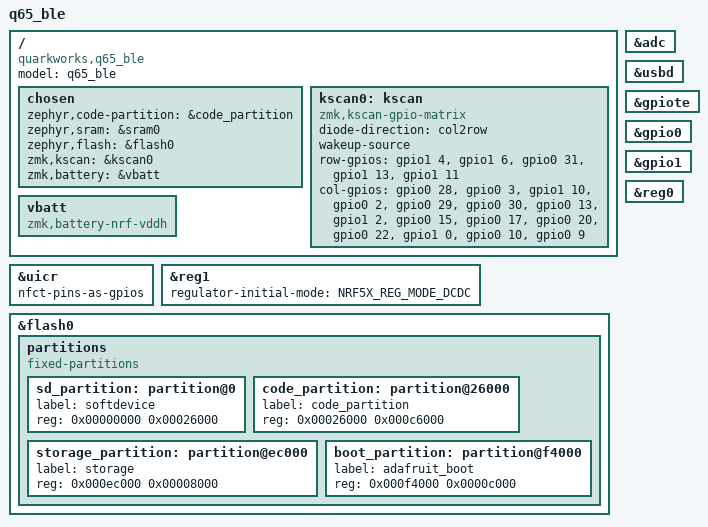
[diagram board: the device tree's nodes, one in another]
/*
 * Copyright (c) 2025 Brandon Beltran
 *
 * SPDX-License-Identifier: MIT
 */

/dts-v1/;

#include <nordic/nrf52840_qiaa.dtsi>

#include "q65_ble-transforms.dtsi"
#include "q65_ble-layouts.dtsi"

/ {
    model = "q65_ble";
    compatible = "quarkworks,q65_ble";

    chosen {
        zephyr,code-partition = &code_partition;
        zephyr,sram = &sram0;
        zephyr,flash = &flash0;
        zmk,kscan = &kscan0;
        zmk,battery = &vbatt;
    };

    kscan0: kscan {
        compatible = "zmk,kscan-gpio-matrix";
        diode-direction = "col2row";
        wakeup-source;

        row-gpios
            = <&gpio1  4 (GPIO_ACTIVE_HIGH | GPIO_PULL_DOWN)>
            , <&gpio1  6 (GPIO_ACTIVE_HIGH | GPIO_PULL_DOWN)>
            , <&gpio0 31 (GPIO_ACTIVE_HIGH | GPIO_PULL_DOWN)>
            , <&gpio1 13 (GPIO_ACTIVE_HIGH | GPIO_PULL_DOWN)>
            , <&gpio1 11 (GPIO_ACTIVE_HIGH | GPIO_PULL_DOWN)>
            ;
        col-gpios
            = <&gpio0 28 GPIO_ACTIVE_HIGH>
            , <&gpio0  3 GPIO_ACTIVE_HIGH>
            , <&gpio1 10 GPIO_ACTIVE_HIGH>
            , <&gpio0  2 GPIO_ACTIVE_HIGH>
            , <&gpio0 29 GPIO_ACTIVE_HIGH>
            , <&gpio0 30 GPIO_ACTIVE_HIGH>
            , <&gpio0 13 GPIO_ACTIVE_HIGH>
            , <&gpio1  2 GPIO_ACTIVE_HIGH>
            , <&gpio0 15 GPIO_ACTIVE_HIGH>
            , <&gpio0 17 GPIO_ACTIVE_HIGH>
            , <&gpio0 20 GPIO_ACTIVE_HIGH>
            , <&gpio0 22 GPIO_ACTIVE_HIGH>
            , <&gpio1  0 GPIO_ACTIVE_HIGH>
            , <&gpio0 10 GPIO_ACTIVE_HIGH>
            , <&gpio0  9 GPIO_ACTIVE_HIGH>
            ;
    };

    vbatt: vbatt {
        compatible = "zmk,battery-nrf-vddh";
    };
    
};

&adc {
    status = "okay";
};

zephyr_udc0: &usbd {
    status = "okay";
};

&gpiote {
    status = "okay";
};

&gpio0 {
    status = "okay";
};

&gpio1 {
    status = "okay";
};

&uicr {
        nfct-pins-as-gpios;
};

&reg0 {
    status = "okay";
};

&reg1 {
    regulator-initial-mode = <NRF5X_REG_MODE_DCDC>;
};


&flash0 {
    /*
     * For more information, see:
     * http://docs.zephyrproject.org/latest/devices/dts/flash_partitions.html
     */
    partitions {
        compatible = "fixed-partitions";
        #address-cells = <1>;
        #size-cells = <1>;

        sd_partition: partition@0 {
            label = "softdevice";
            reg = <0x00000000 0x00026000>;
        };
        code_partition: partition@26000 {
            label = "code_partition";
            reg = <0x00026000 0x000c6000>;
        };

        /*
         * The flash starting at 0x000ec000 and ending at
         * 0x000f3fff is reserved for use by the application.
         */

        /*
         * Storage partition will be used by FCB/LittleFS/NVS
         * if enabled.
         */
        storage_partition: partition@ec000 {
            label = "storage";
            reg = <0x000ec000 0x00008000>;
        };

        boot_partition: partition@f4000 {
            label = "adafruit_boot";
            reg = <0x000f4000 0x0000c000>;
        };
    };
};
